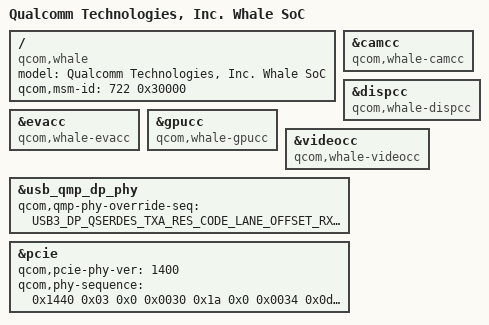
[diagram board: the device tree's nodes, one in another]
// SPDX-License-Identifier: BSD-3-Clause
/*
 * Copyright (c) Qualcomm Technologies, Inc. and/or its subsidiaries.
 */

#include "canoe-v2.dtsi"

/ {
	model = "Qualcomm Technologies, Inc. Whale SoC";
	compatible = "qcom,whale";
	qcom,msm-id = <722 0x30000>;
};

&camcc {
	compatible = "qcom,whale-camcc", "syscon";
};

&dispcc {
	compatible = "qcom,whale-dispcc", "syscon";
};

&evacc {
	compatible = "qcom,whale-evacc", "syscon";
};

&gpucc {
	compatible = "qcom,whale-gpucc", "syscon";
};

&videocc {
	compatible = "qcom,whale-videocc", "syscon";
};

&usb_qmp_dp_phy {
	qcom,qmp-phy-override-seq =
	<USB3_DP_QSERDES_TXA_RES_CODE_LANE_OFFSET_RX 0x04
	 USB3_DP_QSERDES_TXA_LANE_MODE_1 0xF5
	 USB3_DP_QSERDES_TXA_LANE_MODE_3 0x37
	 USB3_DP_QSERDES_TXA_LANE_MODE_4 0x36
	 USB3_DP_QSERDES_RXA_RX_MODE_00_LOW 0X27
	 USB3_DP_QSERDES_RXA_RX_MODE_00_HIGH 0X97
	 USB3_DP_QSERDES_RXA_RX_MODE_00_HIGH2 0xD8
	 USB3_DP_QSERDES_RXA_RX_MODE_00_HIGH4 0xEA
	 USB3_DP_QSERDES_RXA_RX_MODE_01_HIGH2 0x90
	 USB3_DP_QSERDES_RXA_RX_MODE_01_HIGH4 0xA4
	 USB3_DP_QSERDES_TXB_RES_CODE_LANE_OFFSET_RX 0x04
	 USB3_DP_QSERDES_TXB_LANE_MODE_3 0x37
	 USB3_DP_QSERDES_TXB_LANE_MODE_4 0x36
	 USB3_DP_QSERDES_RXB_RX_MODE_00_LOW 0X27
	 USB3_DP_QSERDES_RXB_RX_MODE_00_HIGH 0X97
	 USB3_DP_QSERDES_RXB_RX_MODE_00_HIGH2 0xD8
	 USB3_DP_QSERDES_RXB_RX_MODE_00_HIGH4 0xEA
	 USB3_DP_QSERDES_RXB_RX_MODE_01_HIGH2 0x90
	 USB3_DP_QSERDES_RXB_RX_MODE_01_HIGH4 0xA4>;
};

&pcie {
	qcom,pcie-phy-ver = <1400>;
	qcom,phy-sequence = <0x1440 0x03 0x0
				0x0030 0x1a 0x0
				0x0034 0x0d 0x0
				0x007c 0x00 0x0
				0x0080 0x40 0x0
				0x0084 0x08 0x0
				0x00b4 0x04 0x0
				0x00e0 0x05 0x0
				0x00e4 0x00 0x0
				0x00f4 0x07 0x0
				0x00f8 0x1f 0x0
				0x0058 0x90 0x0
				0x0118 0x02 0x0
				0x011c 0x0d 0x0
				0x0148 0x57 0x0
				0x014c 0x54 0x0
				0x02dc 0x0b 0x0
				0x02ec 0x04 0x0
				0x02f0 0x05 0x0
				0x02f4 0x15 0x0
				0x0370 0x00 0x0
				0x0378 0x89 0x0
				0x03b4 0x2d 0x0		/* Ultra Short channel specific settings */
				0x0128 0x20 0x0
				0x03d8 0x1c 0x0
				0x03dc 0x2f 0x0
				0x03e0 0x84 0x0
				0x02b8 0x01 0x0
				0x02bc 0x05 0x0
				0x02c4 0x00 0x0
				0x02c8 0x00 0x0
				0x02b4 0x00 0x0
				0x0258 0x40 0x0
				0x025c 0x42 0x0
				0x0284 0x18 0x0
				0x0298 0x12 0x0
				0x02ac 0x18 0x0
				0x0418 0xc2 0x0
				0x041c 0xc2 0x0
				0x0420 0x18 0x0
				0x0428 0x0f 0x0
				0x0434 0x62 0x0
				0x0460 0xe4 0x0
				0x0464 0x63 0x0
				0x0468 0xd8 0x0
				0x046c 0x99 0x0
				0x0470 0x6a 0x0
				0x0484 0xa4 0x0
				0x0488 0xa4 0x0
				0x048c 0x28 0x0
				0x0490 0x9f 0x0
				0x0494 0x48 0x0
				0x0498 0x24 0x0
				0x051c 0x01 0x0
				0x0520 0x00 0x0
				0x0578 0x00 0x0
				0x057c 0x08 0x0
				0x0580 0x88 0x0
				0x031c 0xff 0x0
				0x0320 0xff 0x0
				0x0308 0x30 0x0
				0x030c 0x03 0x0
				0x0398 0x1f 0x0
				0x039c 0x1f 0x0
				0x03a0 0x0d 0x0
				0x0830 0x1a 0x0
				0x0834 0x0d 0x0
				0x087c 0x00 0x0
				0x0880 0x40 0x0
				0x0884 0x08 0x0
				0x08b4 0x04 0x0
				0x08e0 0x05 0x0
				0x08e4 0x00 0x0
				0x08f4 0x07 0x0
				0x08f8 0x1f 0x0
				0x0858 0x90 0x0
				0x0918 0x02 0x0
				0x091c 0x0d 0x0
				0x0948 0x57 0x0
				0x094c 0x54 0x0
				0x0adc 0x0b 0x0
				0x0aec 0x04 0x0
				0x0af0 0x05 0x0
				0x0af4 0x15 0x0
				0x0b70 0x00 0x0
				0x0b78 0x89 0x0
				0x0bb4 0x2d 0x0		/* Ultra Short channel specific settings */
				0x0928 0x20 0x0
				0x0bd8 0x1c 0x0
				0x0bdc 0x2f 0x0
				0x0be0 0x84 0x0
				0x0ab8 0x01 0x0
				0x0abc 0x05 0x0
				0x0ac4 0x00 0x0
				0x0ac8 0x00 0x0
				0x0ab4 0x00 0x0
				0x0a58 0x40 0x0
				0x0a5c 0x42 0x0
				0x0a84 0x18 0x0
				0x0a98 0x12 0x0
				0x0aac 0x18 0x0
				0x0c18 0xc2 0x0
				0x0c1c 0xc2 0x0
				0x0c20 0x18 0x0
				0x0c28 0x0f 0x0
				0x0c34 0x62 0x0
				0x0c60 0xe4 0x0
				0x0c64 0x63 0x0
				0x0c68 0xd8 0x0
				0x0c6c 0x99 0x0
				0x0c70 0x6a 0x0
				0x0c84 0xa4 0x0
				0x0c88 0xa4 0x0
				0x0c8c 0x28 0x0
				0x0c90 0x9f 0x0
				0x0c94 0x48 0x0
				0x0c98 0x24 0x0
				0x0d1c 0x01 0x0
				0x0d20 0x00 0x0
				0x0d78 0x00 0x0
				0x0d7c 0x08 0x0
				0x0d80 0x88 0x0
				0x0b1c 0xff 0x0
				0x0b20 0xff 0x0
				0x0b08 0x30 0x0
				0x0b0c 0x03 0x0
				0x0b98 0x1f 0x0
				0x0b9c 0x1f 0x0
				0x0ba0 0x0d 0x0
				0x1000 0x93 0x0
				0x1004 0x01 0x0
				0x1010 0x06 0x0
				0x1014 0x16 0x0
				0x1018 0x36 0x0
				0x101c 0x04 0x0
				0x1020 0x0a 0x0
				0x1024 0x1a 0x0
				0x1028 0x34 0x0
				0x1030 0x55 0x0
				0x1034 0x55 0x0
				0x1038 0x01 0x0
				0x103c 0x01 0x0
				0x1040 0x7f 0x0
				0x1060 0xf8 0x0
				0x1064 0x01 0x0
				0x1070 0x06 0x0
				0x1074 0x16 0x0
				0x1078 0x36 0x0
				0x107c 0x0a 0x0
				0x1080 0x04 0x0
				0x1084 0x0d 0x0
				0x1088 0x41 0x0
				0x1090 0xab 0x0
				0x1094 0xaa 0x0
				0x1098 0x01 0x0
				0x109c 0x00 0x0
				0x10bc 0x0a 0x0
				0x10c0 0x01 0x0
				0x10cc 0x62 0x0
				0x10d0 0x02 0x0
				0x10dc 0x14 0x0
				0x10e0 0x90 0x0
				0x10e4 0x82 0x0
				0x10f4 0x0f 0x0
				0x1110 0x08 0x0
				0x1120 0x46 0x0
				0x1124 0x04 0x0
				0x1140 0x14 0x0
				0x1164 0x34 0x0
				0x1170 0xa0 0x0
				0x1174 0x16 0x0
				0x1184 0x88 0x0
				0x1188 0x04 0x0
				0x1198 0x0f 0x0
				0x12b4 0x02 0x0
				0x1570 0x17 0x0		/* Ultra Short channel specific settings */
				0x1578 0x2e 0x0
				0x1590 0xcc 0x0
				0x15b8 0x40 0x0
				0x15dc 0x04 0x0
				0x15e0 0x02 0x0
				0x1818 0xc0 0x0
				0x15f8 0x00 0x0
				0x15fc 0x22 0x0
				0x180c 0x1d 0x0
				0x181c 0xc1 0x0
				0x1890 0x00 0x0
				0x18a0 0x16 0x0
				0x18f0 0x27 0x0
				0x18f4 0x27 0x0
				0x1908 0x02 0x0
				0x195c 0x2e 0x0
				0x197c 0x03 0x0
				0x1984 0x28 0x0
				0x198c 0x00 0x0
				0x19ac 0x02 0x0
				0x19c0 0x02 0x0
				0X19d0 0x1f 0x0
				0x1400 0x00 0x0
				0x1444 0x03 0x0>;
};
